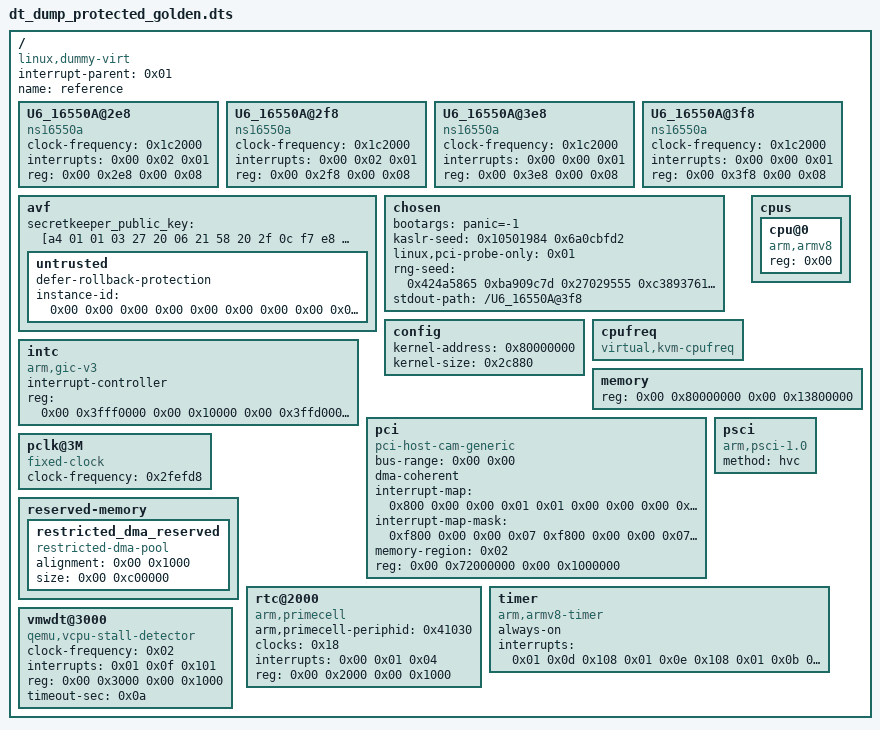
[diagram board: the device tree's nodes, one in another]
/dts-v1/;

/ {
	#address-cells = <0x02>;
	#size-cells = <0x02>;
	compatible = "linux,dummy-virt";
	interrupt-parent = <0x01>;
	name = "reference";

	U6_16550A@2e8 {
		clock-frequency = <0x1c2000>;
		compatible = "ns16550a";
		interrupts = <0x00 0x02 0x01>;
		reg = <0x00 0x2e8 0x00 0x08>;
	};

	U6_16550A@2f8 {
		clock-frequency = <0x1c2000>;
		compatible = "ns16550a";
		interrupts = <0x00 0x02 0x01>;
		reg = <0x00 0x2f8 0x00 0x08>;
	};

	U6_16550A@3e8 {
		clock-frequency = <0x1c2000>;
		compatible = "ns16550a";
		interrupts = <0x00 0x00 0x01>;
		reg = <0x00 0x3e8 0x00 0x08>;
	};

	U6_16550A@3f8 {
		clock-frequency = <0x1c2000>;
		compatible = "ns16550a";
		interrupts = <0x00 0x00 0x01>;
		reg = <0x00 0x3f8 0x00 0x08>;
	};

	__symbols__ {
		intc = "/intc";
	};

	avf {
		secretkeeper_public_key = [a4 01 01 03 27 20 06 21 58 20 2f 0c f7 e8 a1 ab 24 b5 96 c5 12 0f 85 d0 31 a7 ae f4 21 5b 95 b8 26 7d 32 39 18 c1 c0 29 e4 1f];

		untrusted {
			defer-rollback-protection;
			instance-id = <0x00 0x00 0x00 0x00 0x00 0x00 0x00 0x00 0x00 0x00 0x00 0x00 0x00 0x00 0x00 0x00>;
		};
	};

	chosen {
		bootargs = "panic=-1";
		kaslr-seed = <0x10501984 0x6a0cbfd2>;
		linux,pci-probe-only = <0x01>;
		rng-seed = <0x424a5865 0xba909c7d 0x27029555 0xc3893761 0x8d90f65f 0xaaea2869 0xd28d6a15 0x50b6ff18 0x7163a77d 0x99df957d 0x312e254 0x5c90379c 0xb1ca8939 0x8b5fb089 0xa9d29804 0x53a1c531 0xc5435a15 0xaa601254 0x5e183c21 0x877e8e05 0xfe4769d8 0x4ceec548 0xd3f5bc36 0xd75319d7 0xb34d09 0xb16fa603 0x25785c77 0x9acc8c95 0xa171121f 0x1a270c0e 0xfb42f08b 0x5d5fbfaa 0x383de1a 0x9b2553e6 0x93d7aae2 0xe7b4bb90 0xbef9ed60 0x8951f6f9 0x84d1c2a8 0x34de5a57 0x36d28c02 0xf585f452 0x1c846c21 0x54cf2baf 0xc0bd9b4b 0xdd8fe8b5 0x76acc116 0x28b86f4a 0xa9292f45 0x7e3a3e6b 0x81f957b3 0xa6325ca3 0x365442ed 0xf8bf23f9 0xcd36f96c 0xab2015eb 0x1fd02031 0x72012f6d 0xc06a6d10 0xd58b1703 0x98d1322d 0xba278227 0x69a85892 0xc697b2da>;
		stdout-path = "/U6_16550A@3f8";
	};

	config {
		kernel-address = <0x80000000>;
		kernel-size = <0x2c880>;
	};

	cpufreq {
		compatible = "virtual,kvm-cpufreq";
	};

	cpus {
		#address-cells = <0x01>;
		#size-cells = <0x00>;

		cpu@0 {
			compatible = "arm,armv8";
			device_type = "cpu";
			phandle = <0x100>;
			reg = <0x00>;
		};
	};

	intc {
		#address-cells = <0x02>;
		#interrupt-cells = <0x03>;
		#size-cells = <0x02>;
		compatible = "arm,gic-v3";
		interrupt-controller;
		phandle = <0x01>;
		reg = <0x00 0x3fff0000 0x00 0x10000 0x00 0x3ffd0000 0x00 0x20000>;
	};

	memory {
		device_type = "memory";
		reg = <0x00 0x80000000 0x00 0x13800000>;
	};

	pci {
		#address-cells = <0x03>;
		#interrupt-cells = <0x01>;
		#size-cells = <0x02>;
		bus-range = <0x00 0x00>;
		compatible = "pci-host-cam-generic";
		device_type = "pci";
		dma-coherent;
		interrupt-map = <0x800 0x00 0x00 0x01 0x01 0x00 0x00 0x00 0x04 0x04 0x1000 0x00 0x00 0x01 0x01 0x00 0x00 0x00 0x05 0x04 0x1800 0x00 0x00 0x01 0x01 0x00 0x00 0x00 0x06 0x04 0x2000 0x00 0x00 0x01 0x01 0x00 0x00 0x00 0x07 0x04 0x2800 0x00 0x00 0x01 0x01 0x00 0x00 0x00 0x08 0x04 0x3000 0x00 0x00 0x01 0x01 0x00 0x00 0x00 0x09 0x04 0x3800 0x00 0x00 0x01 0x01 0x00 0x00 0x00 0x0a 0x04>;
		interrupt-map-mask = <0xf800 0x00 0x00 0x07 0xf800 0x00 0x00 0x07 0xf800 0x00 0x00 0x07 0xf800 0x00 0x00 0x07 0xf800 0x00 0x00 0x07 0xf800 0x00 0x00 0x07 0xf800 0x00 0x00 0x07>;
		memory-region = <0x02>;
		ranges = <0x3000000 0x00 0x70000000 0x00 0x70000000 0x00 0x2000000 0x43000000 0x00 0x94000000 0x00 0x94000000 0xff 0x6c000000>;
		reg = <0x00 0x72000000 0x00 0x1000000>;
	};

	pclk@3M {
		#clock-cells = <0x00>;
		clock-frequency = <0x2fefd8>;
		compatible = "fixed-clock";
		phandle = <0x18>;
	};

	psci {
		compatible = "arm,psci-1.0\0arm,psci-0.2";
		method = "hvc";
	};

	reserved-memory {
		#address-cells = <0x02>;
		#size-cells = <0x02>;
		ranges;

		restricted_dma_reserved {
			alignment = <0x00 0x1000>;
			compatible = "restricted-dma-pool";
			phandle = <0x02>;
			size = <0x00 0xc00000>;
		};
	};

	rtc@2000 {
		arm,primecell-periphid = <0x41030>;
		clock-names = "apb_pclk";
		clocks = <0x18>;
		compatible = "arm,primecell";
		interrupts = <0x00 0x01 0x04>;
		reg = <0x00 0x2000 0x00 0x1000>;
	};

	timer {
		always-on;
		compatible = "arm,armv8-timer";
		interrupts = <0x01 0x0d 0x108 0x01 0x0e 0x108 0x01 0x0b 0x108 0x01 0x0a 0x108>;
	};

	vmwdt@3000 {
		clock-frequency = <0x02>;
		compatible = "qemu,vcpu-stall-detector";
		interrupts = <0x01 0x0f 0x101>;
		reg = <0x00 0x3000 0x00 0x1000>;
		timeout-sec = <0x0a>;
	};
};
